# R7FA4L1BD register map
Vendor: Renesas Electronics Corporation; Series: RA4; File version: 0.90.02
CPU: CM33 r0p4, little endian, MPU, FPU, VTOR, 4 interrupt priority bits, 96 interrupts
Registers are 32-bit, read-write, reset 0x0 unless marked. A register's access mark holds for its fields unless they carry their own. Offsets are from the block's base; [hi:lo] are bit positions; 'fields as' and 'values as' point back to an identical list.

## IIC0WU — IIC0 Wake-up Unit
Base 0x4009F014
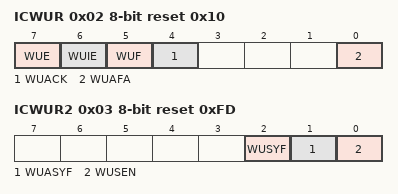
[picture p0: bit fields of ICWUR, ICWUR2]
0x02 ICWUR 8-bit reset 0x10 — I2C Bus Wakeup Unit Register
  [7] WUE — Wakeup Function Enable
    0=Disable wakeup function; 1=Enable wakeup function
  [6] WUIE — Wakeup Interrupt Request Enable
    0=Disable wakeup interrupt request (IIC0_WUI); 1=Enable wakeup interrupt request (IIC0_WUI)
  [5] WUF — Wakeup Event Occurrence Flag
    0=Slave address not matching during wakeup; 1=Slave address matching during wakeup
  [4] WUACK — ACK Bit for Wakeup Mode
  [0] WUAFA — Wakeup Analog Filter Additional Selection
    0=Do not add the wakeup analog filter; 1=Add the wakeup analog filter
0x03 ICWUR2 8-bit reset 0xFD — I2C Bus Wakeup Unit Register 2
  [2] WUSYF ro — Wakeup Function Synchronous Operation Status Flag
    0=IIC asynchronous circuit enable condition; 1=IIC synchronous circuit enable condition
  [1] WUASYF ro — Wakeup Function Asynchronous Operation Status Flag
    0=IIC synchronous circuit enable condition; 1=IIC asynchronous circuit enable condition
  [0] WUSEN — Wakeup Function Synchronous Enable
    0=IIC asynchronous circuit enable; 1=IIC synchronous circuit enable

## ACMPLP — Low-Power Analog Comparator
Base 0x400F4000
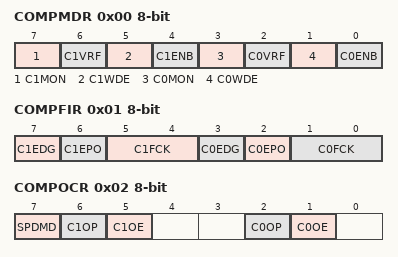
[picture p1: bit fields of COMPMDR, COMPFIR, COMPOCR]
0x00 COMPMDR 8-bit — ACMPLP Mode Setting Register
  [7] C1MON ro — ACMPLP1 Monitor Flag
  [6] C1VRF — ACMPLP1 Reference Voltage Selection
    0=Select CMPREF1 input as ACMPLP1 reference voltage; 1=Select internal reference voltage (Vref) as ACMPLP1 reference voltage
  [5] C1WDE — ACMPLP1 Window Function Mode Enable
    0=Disable ACMPLP1 window function mode; 1=Enable ACMPLP1 window function mode
  [4] C1ENB — ACMPLP1 Operation Enable
    0=Disable ACMPLP1 operation; 1=Enable ACMPLP1 operation
  [3] C0MON ro — ACMPLP0 Monitor Flag
  [2] C0VRF — ACMPLP0 Reference Voltage Selection
    0=Select CMPREF0 input as ACMPLP0 reference voltage; 1=Select internal reference voltage (Vref) as ACMPLP0 reference voltage
  [1] C0WDE — ACMPLP0 Window Function Mode Enable
    0=Disable window function for ACMPLP0; 1=Enable window function for ACMPLP0
  [0] C0ENB — ACMPLP0 Operation Enable
    0=Disable comparator channel ACMPLP0; 1=Enable comparator channel ACMPLP0
0x01 COMPFIR 8-bit — ACMPLP Filter Control Register
  [7] C1EDG — ACMPLP1 Edge Detection Selection
    0=Interrupt and ELC event request by one-edge detection; 1=Interrupt and ELC event request by both-edge detection
  [6] C1EPO — ACMPLP1 Edge Polarity Switching
    0=Interrupt and ELC event request on rising edge; 1=Interrupt and ELC event request on falling edge
  [5:4] C1FCK — ACMPLP1 Filter Select
    0=No Sampling (bypass); 1=Sampling at PCLKB; 2=Sampling at PCLKB/8; 3=Sampling at PCLKB/32
  [3] C0EDG — ACMPLP0 Edge Detection Selection
    values as C1EDG
  [2] C0EPO — ACMPLP0 Edge Polarity Switching
    values as C1EPO
  [1:0] C0FCK — ACMPLP0 Filter Select
    values as C1FCK
0x02 COMPOCR 8-bit — ACMPLP Output Control Register
  [7] SPDMD — ACMPLP0/ACMPLP1 Speed Selection
    0=Low-speed mode; 1=High-speed mode
  [6] C1OP — ACMPLP1 VCOUT Output Polarity Selection
    0=Non-inverted; 1=Inverted
  [5] C1OE — ACMPLP1 VCOUT Pin Output Enable
    0=Disabled; 1=Enabled
  [2] C0OP — ACMPLP0 VCOUT Output Polarity Selection
    0=Non-inverted; 1=Inverted
  [1] C0OE — ACMPLP0 VCOUT Pin Output Enable
    0=Disabled; 1=Enabled

## CRC — Cyclic Redundancy Check Calculator
Base 0x40108000
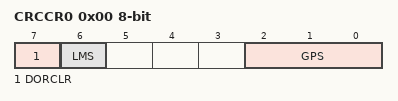
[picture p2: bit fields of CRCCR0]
0x00 CRCCR0 8-bit — CRC Control Register 0
  [7] DORCLR wo — CRCDOR/CRCDOR_HA/CRCDOR_BY Register Clear
    0=No effect; 1=Clear the CRCDOR/CRCDOR_HA/CRCDOR_BY register
  [6] LMS — CRC Calculation Switching
    0=Generate CRC code for LSB-first communication; 1=Generate CRC code for MSB-first communication
  [2:0] GPS — CRC Generating Polynomial Switching
    1=8-bit CRC-8 (X8 + X2 + X + 1); 2=16-bit CRC-16 (X16 + X15 + X2 + 1); 3=16-bit CRC-CCITT (X16 + X12 + X5 + 1); 4=32-bit CRC-32 (X32 + X26 + X23 + X22 + X16 + X12 + X11 +X10 + X8 + X7 + X5 + X4 + X2 + X + 1); 5=32-bit CRC-32C (X32 + X28 + X27 + X26 + X25 + X23 + X22 + X20 + X19 + X18 + X14 + X13 + X11 + X10 + X9 + X8 + X6 + 1); other=Others (No calculation is executed)
0x04 CRCDIR — CRC Data Input Register
0x04 CRCDIR_BY 8-bit (alternate view of CRCDIR) — CRC Data Input Register
0x08 CRCDOR — CRC Data Output Register
0x08 CRCDOR_HA 16-bit (alternate view of CRCDOR) — CRC Data Output Register
0x08 CRCDOR_BY 8-bit (alternate view of CRCDOR) — CRC Data Output Register
